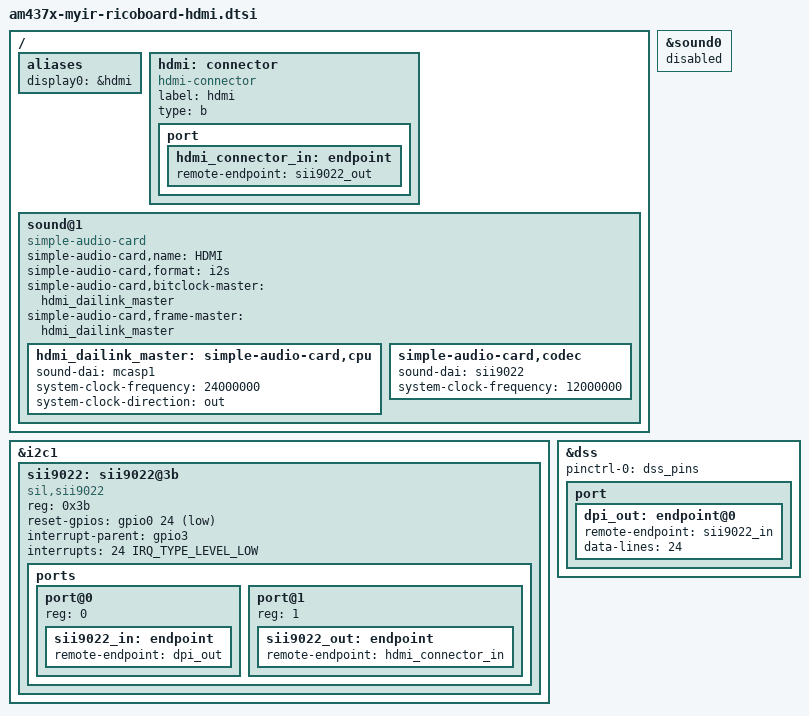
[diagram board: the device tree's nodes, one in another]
/*
 * Device Tree Source for am4378 Ricoboard
 *
 * Copyright (C) 2013 Texas Instruments Incorporated - http://www.ti.com/
 *
 * This file is licensed under the terms of the GNU General Public License
 * version 2.  This program is licensed "as is" without any warranty of any
 * kind, whether express or implied.
 */

/ {
	aliases {
		display0 = &hdmi;
	};

	hdmi: connector {
		compatible = "hdmi-connector";
		label = "hdmi";

		type = "b";

		port {
			hdmi_connector_in: endpoint {
				remote-endpoint = <&sii9022_out>;
			};
		};
	};

	sound@1 {
		compatible = "simple-audio-card";
		simple-audio-card,name = "HDMI";
		simple-audio-card,format = "i2s";
		simple-audio-card,bitclock-master = <&hdmi_dailink_master>;
		simple-audio-card,frame-master = <&hdmi_dailink_master>;
		hdmi_dailink_master: simple-audio-card,cpu {
			sound-dai = <&mcasp1>;
			system-clock-frequency = <24000000>;
			system-clock-direction = "out";
		};

		simple-audio-card,codec {
			sound-dai = <&sii9022>;
			system-clock-frequency = <12000000>;
		};
	};
};

&sound0 {
	status = "disabled";
};

&i2c1 {
	sii9022: sii9022@3b {
		#sound-dai-cells = <0>;
		compatible = "sil,sii9022";
		reg = <0x3b>;

		/* sii9022_gpio_pins_default: sii9022_gpio_pins_default */
		reset-gpios = <&gpio0 24 GPIO_ACTIVE_LOW>;

		/* sii9022_gpio_pins - spi2_sclk.gpio3_24.gpio0_22.hdmi_intn */
		/* interrupts-extended = <&gpio3 24 IRQ_TYPE_EDGE_FALLING>; */
		interrupt-parent = <&gpio3>;
		interrupts = <24 IRQ_TYPE_LEVEL_LOW>;

		ports {
			#address-cells = <1>;
			#size-cells = <0>;

			port@0 {
				reg = <0>;

				sii9022_in: endpoint {
					remote-endpoint = <&dpi_out>;
				};
			};

			port@1 {
				reg = <1>;

				sii9022_out: endpoint {
					remote-endpoint = <&hdmi_connector_in>;
				};
			};
		};
	};
};


&dss {
	status = "ok";

	pinctrl-names = "default";
	pinctrl-0 = <&dss_pins>;

	port {
		dpi_out: endpoint@0 {
			remote-endpoint = <&sii9022_in>;
			data-lines = <24>;
		};
	};

};

